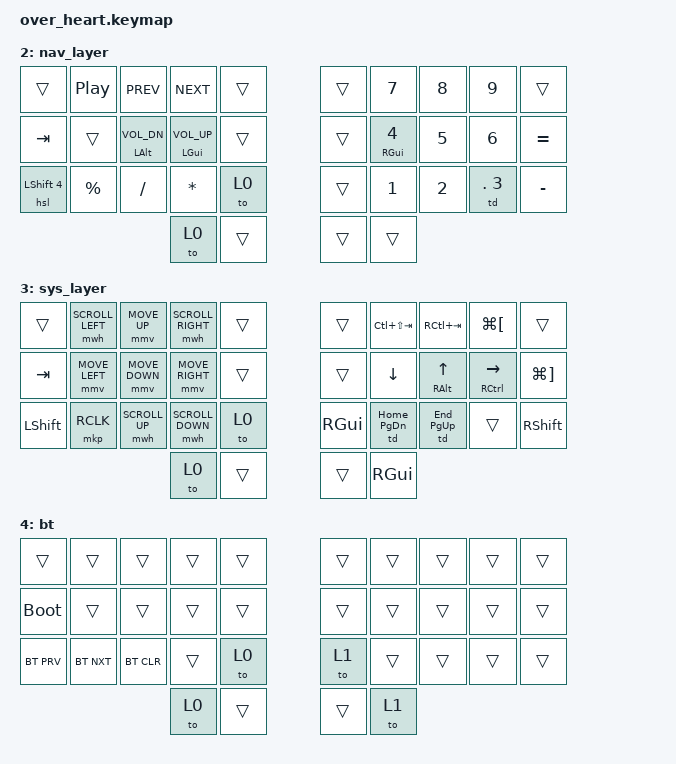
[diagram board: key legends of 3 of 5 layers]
#include <behaviors.dtsi>
#include <dt-bindings/zmk/keys.h>
#include <dt-bindings/zmk/bt.h>
#include <dt-bindings/zmk/mouse.h>

&mt {
    flavor = "tap-preferred";
    tapping_term_ms = <200>;
};

/ {

        keymap {
                compatible = "zmk,keymap";

       		base_layer {
		bindings = <
		&kp QUOT	&kp COMMA	&kp DOT		&kp P		&kp Y			&kp F		&kp G		&kp C		&kp R		&kp L
		&kp A		&hm LCTL O	&hm LALT E	&hm LGUI U	&kp I			&kp D		&hm RGUI H	&hm RALT T	&hm RCTL N	&kp S
		&hs LSHIFT SEMI	&kp Q	&kp J		&kp K		&mt LC(LS(LALT)) X	&kp B	&kp H		&kp W		&td V		&hs RSHIFT Z
          									&to ! 		&to 2			&kp RET		&kp LC(LS(LALT)) SPC
		>;
		};

       		num_layer {
		bindings = <
		&trans  &kp ATSN   &td LC(LG(LS(N4))) LS(N3) &kp DLLR    &trans		&trans &kp LS(COMMA) &kp LS(DOT) &kp CARET &trans
		&kp TAB    &hm LCTL EQUAL    &hm LALT LA(RBKT)      &hm LGUI LA(LS(RBKT))     &trans 		&trans &hm RGUI LBRC  &hm RALT RBRC &hm RCTL PIPE  &kp AMPS
  		&hs LSHIFT TILDE    &kp GRAVE 	&kp LA(LBKT) &kp LA(LS(LBKT))  &to 0 	&to 2 &kp LPRN &kp RPRN &kp RBKT  &kp RSHIFT
					    &to 0 &trans  					&trans &to 2
		>;
		};

			nav_layer {
		bindings = <
		&trans &kp C_PP &kp C_PREV  &kp C_NEXT  &trans    			&trans  &kp N7 &kp N8 &kp N9 &trans
		&kp TAB  &trans   &hm LALT C_VOL_DN  &hm LGUI C_VOL_UP  &trans  			&trans &hm RGUI N4  &kp N5  &kp N6   &kp EQUAL
		&hsl LSHIFT 4  &kp PRCNT &kp SLASH &kp STAR &to 0 &trans &kp N1 &kp N2 &td DOT N3  &kp MINUS
					  &to 0 &trans  				&trans &trans
		>;
		};

			sys_layer {
		bindings = <
		&trans  &mwh SCROLL_LEFT    &mmv MOVE_UP    &mwh SCROLL_RIGHT    &trans &trans    &kp LC(LS(TAB))   &kp RC(TAB) &kp LG(LBKT) &trans
		&kp TAB &mmv MOVE_LEFT &mmv MOVE_DOWN &mmv MOVE_RIGHT &trans  						&trans &kp DOWN  &hm RALT UP &hm RCTL RIGHT &kp LG(RBKT)
		&kp LSHIFT &mkp RCLK  &mwh SCROLL_UP &mwh SCROLL_DOWN &to 0   				&kp RGUI &td HOME PG_DN  &td END PG_UP  &trans &kp RSHIFT
					 &to 0 &trans &trans &kp RGUI
		>;
		};
			bt {
		bindings = <
		&trans  &trans &trans &trans &trans &trans &trans &trans &trans &trans
		&bootloader  &trans &trans &trans &trans &trans &trans &trans &trans &trans
		&bt BT_PRV  &bt BT_NXT &bt BT_CLR &trans &to 0   				&to 1 &trans  &trans  &trans &trans
					 &to 0 &trans  					&trans &to 1
		>;
		};

	};

};
